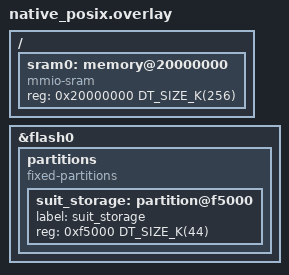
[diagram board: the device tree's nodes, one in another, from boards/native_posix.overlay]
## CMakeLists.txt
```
#
# Copyright (c) 2022 Nordic Semiconductor ASA
#
# SPDX-License-Identifier: LicenseRef-Nordic-5-Clause
#

cmake_minimum_required(VERSION 3.20.0)

find_package(Zephyr REQUIRED HINTS $ENV{ZEPHYR_BASE})

project(integration_test_suit_storage)
include(../cmake/test_template.cmake)

# Link with the CMake target, that includes SUIT platform internal APIs header
zephyr_library_link_libraries(suit_utils)
zephyr_library_link_libraries(suit_storage_interface)
zephyr_library_link_libraries(suit_update_magic_values)
```

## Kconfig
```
#
# Copyright (c) 2025 Nordic Semiconductor ASA
#
# SPDX-License-Identifier: LicenseRef-Nordic-5-Clause
#

rsource "../tests/Kconfig"

source "Kconfig.zephyr"
```

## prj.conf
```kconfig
#
# Copyright (c) 2022 Nordic Semiconductor ASA
#
# SPDX-License-Identifier: LicenseRef-Nordic-5-Clause
#

CONFIG_ZTEST=y

CONFIG_SUIT=y
CONFIG_SUIT_UTILS=y
CONFIG_SUIT_STORAGE=y
CONFIG_SUIT_STORAGE_N_UPDATE_REGIONS=3
CONFIG_SUIT_METADATA=y

CONFIG_ZCBOR=y
CONFIG_ZCBOR_CANONICAL=y

CONFIG_FLASH=y
```

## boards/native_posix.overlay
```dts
/*
 * Copyright (c) 2022 Nordic Semiconductor ASA
 *
 * SPDX-License-Identifier: LicenseRef-Nordic-5-Clause
 */

&flash0 {
	partitions {
		compatible = "fixed-partitions";
		#address-cells = <1>;
		#size-cells = <1>;

		/* Use the last 44KB of NVM as suit storage. */
		suit_storage: partition@f5000 {
			label = "suit_storage";
			reg = <0xf5000 DT_SIZE_K(44)>;
		};
	};
};

/ {
	sram0: memory@20000000 {
		compatible = "mmio-sram";
		reg = <0x20000000 DT_SIZE_K(256)>;
	};
};
```

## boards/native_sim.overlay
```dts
/*
 * Copyright (c) 2022 Nordic Semiconductor ASA
 *
 * SPDX-License-Identifier: LicenseRef-Nordic-5-Clause
 */

&flash0 {
	partitions {
		compatible = "fixed-partitions";
		#address-cells = <1>;
		#size-cells = <1>;

		/* Use the last 48KB of NVM as suit storage. */
		suit_storage: partition@f4000 {
			reg = <0xf4000 DT_SIZE_K(48)>;
		};
	};
};

/ {
	sram0: memory@20000000 {
		compatible = "mmio-sram";
		reg = <0x20000000 DT_SIZE_K(256)>;
	};
};
```

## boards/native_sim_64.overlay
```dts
/*
 * Copyright (c) 2022 Nordic Semiconductor ASA
 *
 * SPDX-License-Identifier: LicenseRef-Nordic-5-Clause
 */

&flash0 {
	partitions {
		compatible = "fixed-partitions";
		#address-cells = <1>;
		#size-cells = <1>;

		/* Use the last 44KB of NVM as suit storage. */
		suit_storage: partition@f5000 {
			reg = <0xf5000 DT_SIZE_K(44)>;
		};
	};
};

/ {
	sram0: memory@20000000 {
		compatible = "mmio-sram";
		reg = <0x20000000 DT_SIZE_K(256)>;
	};
};
```

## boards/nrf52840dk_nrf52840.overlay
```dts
/*
 * Copyright (c) 2022 Nordic Semiconductor ASA
 *
 * SPDX-License-Identifier: LicenseRef-Nordic-5-Clause
 */

&flash0 {
	partitions {
		compatible = "fixed-partitions";
		#address-cells = <1>;
		#size-cells = <1>;

		/* Use the last 48KB of NVM as suit storage. */
		suit_storage: partition@f4000 {
			reg = <0xf4000 DT_SIZE_K(48)>;
		};
	};
};
```

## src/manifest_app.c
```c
/*
 * Copyright (c) 2023 Nordic Semiconductor ASA
 *
 * SPDX-License-Identifier: LicenseRef-Nordic-5-Clause
 */

#include <stdint.h>
#include <stddef.h>

/** @brief SUIT envelope generated using the manifest/manifest_app.yaml input file.
 *
 * @details This envelope contains 256-byte random numbers attached as an integrated
 *          payload and fetched directly into the memory-mapped region during install step.
 *          The envelope has been signed using the manifest/key_private.pem key.
 *
 * @note Please use the manifest_common/regenerate.sh script for regenerating payloads.
 */
uint8_t manifest_app_buf[] = {
	0xD8, 0x6B, 0xA4, 0x02, 0x58, 0x7A, 0x82, 0x58, 0x24, 0x82, 0x2F, 0x58, 0x20, 0x4E, 0xDE,
	0x20, 0x62, 0xD7, 0x21, 0x32, 0xB2, 0xF4, 0x4C, 0x2C, 0x8B, 0x10, 0x41, 0xB1, 0x76, 0x3C,
	0x6E, 0x42, 0x2A, 0x82, 0xE9, 0x95, 0x91, 0x2B, 0x3B, 0x3A, 0x41, 0xC7, 0x96, 0xA3, 0x9B,
	0x58, 0x51, 0xD2, 0x84, 0x4A, 0xA2, 0x01, 0x26, 0x04, 0x45, 0x1A, 0x40, 0x02, 0x21, 0x00,
	0xA0, 0xF6, 0x58, 0x40, 0x39, 0x9A, 0x16, 0x37, 0xEC, 0x61, 0xA4, 0x17, 0x40, 0x22, 0xE7,
	0x0B, 0xA4, 0x9F, 0x37, 0x93, 0xC9, 0x32, 0xD9, 0x6A, 0x16, 0x42, 0x10, 0x2E, 0xB9, 0x59,
	0x62, 0x1C, 0x04, 0x30, 0x5D, 0xB8, 0x8A, 0x86, 0x95, 0xEB, 0x5C, 0xFC, 0x99, 0x9C, 0xE3,
	0x23, 0x00, 0xB3, 0xDB, 0xE7, 0xC0, 0x60, 0x56, 0x72, 0x6D, 0x7C, 0xD0, 0x94, 0x69, 0xB1,
	0x72, 0x64, 0xDD, 0x79, 0x44, 0x05, 0x18, 0xBC, 0x03, 0x58, 0xDB, 0xA8, 0x01, 0x01, 0x02,
	0x01, 0x03, 0x58, 0x70, 0xA2, 0x02, 0x81, 0x84, 0x44, 0x63, 0x4D, 0x45, 0x4D, 0x41, 0x02,
	0x45, 0x1A, 0x0E, 0x0A, 0xA0, 0x00, 0x45, 0x1A, 0x00, 0x07, 0xF8, 0x00, 0x04, 0x58, 0x56,
	0x86, 0x14, 0xA4, 0x01, 0x50, 0x76, 0x17, 0xDA, 0xA5, 0x71, 0xFD, 0x5A, 0x85, 0x8F, 0x94,
	0xE2, 0x8D, 0x73, 0x5C, 0xE9, 0xF4, 0x02, 0x50, 0x08, 0xC1, 0xB5, 0x99, 0x55, 0xE8, 0x5F,
	0xBC, 0x9E, 0x76, 0x7B, 0xC2, 0x9C, 0xE1, 0xB0, 0x4D, 0x03, 0x58, 0x24, 0x82, 0x2F, 0x58,
	0x20, 0x5F, 0xC3, 0x54, 0xBF, 0x8E, 0x8C, 0x50, 0xFB, 0x4F, 0xBC, 0x2C, 0xFA, 0xEB, 0x04,
	0x53, 0x41, 0xC9, 0x80, 0x6D, 0xEA, 0xBD, 0xCB, 0x41, 0x54, 0xFB, 0x79, 0xCC, 0xA4, 0xF0,
	0xC9, 0x8C, 0x12, 0x0E, 0x19, 0x01, 0x00, 0x01, 0x0F, 0x02, 0x0F, 0x07, 0x43, 0x82, 0x03,
	0x0F, 0x09, 0x43, 0x82, 0x17, 0x02, 0x11, 0x52, 0x86, 0x14, 0xA1, 0x15, 0x69, 0x23, 0x66,
	0x69, 0x6C, 0x65, 0x2E, 0x62, 0x69, 0x6E, 0x15, 0x02, 0x03, 0x0F, 0x17, 0x82, 0x2F, 0x58,
	0x20, 0x47, 0x37, 0x59, 0x1A, 0x1E, 0x62, 0xE1, 0x47, 0xD3, 0x22, 0x73, 0xA9, 0x14, 0x4C,
	0x55, 0xD9, 0x90, 0xA8, 0x51, 0x41, 0x8C, 0x82, 0x68, 0x30, 0x4C, 0xE1, 0x6F, 0x23, 0x6F,
	0x26, 0x5D, 0x13, 0x05, 0x82, 0x4C, 0x6B, 0x49, 0x4E, 0x53, 0x54, 0x4C, 0x44, 0x5F, 0x4D,
	0x46, 0x53, 0x54, 0x50, 0x08, 0xC1, 0xB5, 0x99, 0x55, 0xE8, 0x5F, 0xBC, 0x9E, 0x76, 0x7B,
	0xC2, 0x9C, 0xE1, 0xB0, 0x4D, 0x17, 0x58, 0x9B, 0xA1, 0x62, 0x65, 0x6E, 0xA1, 0x84, 0x44,
	0x63, 0x4D, 0x45, 0x4D, 0x41, 0x02, 0x45, 0x1A, 0x0E, 0x0A, 0xA0, 0x00, 0x45, 0x1A, 0x00,
	0x07, 0xF8, 0x00, 0xA6, 0x01, 0x78, 0x18, 0x4E, 0x6F, 0x72, 0x64, 0x69, 0x63, 0x20, 0x53,
	0x65, 0x6D, 0x69, 0x63, 0x6F, 0x6E, 0x64, 0x75, 0x63, 0x74, 0x6F, 0x72, 0x20, 0x41, 0x53,
	0x41, 0x02, 0x6F, 0x6E, 0x52, 0x46, 0x35, 0x34, 0x48, 0x32, 0x30, 0x5F, 0x63, 0x70, 0x75,
	0x61, 0x70, 0x70, 0x03, 0x6E, 0x6E, 0x6F, 0x72, 0x64, 0x69, 0x63, 0x73, 0x65, 0x6D, 0x69,
	0x2E, 0x63, 0x6F, 0x6D, 0x04, 0x78, 0x1D, 0x54, 0x68, 0x65, 0x20, 0x6E, 0x52, 0x46, 0x35,
	0x34, 0x48, 0x32, 0x30, 0x20, 0x61, 0x70, 0x70, 0x6C, 0x69, 0x63, 0x61, 0x74, 0x69, 0x6F,
	0x6E, 0x20, 0x63, 0x6F, 0x72, 0x65, 0x05, 0x78, 0x1A, 0x53, 0x61, 0x6D, 0x70, 0x6C, 0x65,
	0x20, 0x61, 0x70, 0x70, 0x6C, 0x69, 0x63, 0x61, 0x74, 0x69, 0x6F, 0x6E, 0x20, 0x63, 0x6F,
	0x72, 0x65, 0x20, 0x46, 0x57, 0x06, 0x66, 0x76, 0x31, 0x2E, 0x30, 0x2E, 0x30, 0x69, 0x23,
	0x66, 0x69, 0x6C, 0x65, 0x2E, 0x62, 0x69, 0x6E, 0x59, 0x01, 0x00, 0xC7, 0x9C, 0xAB, 0x9D,
	0xE8, 0x33, 0x7F, 0x30, 0x14, 0xEB, 0xAC, 0x02, 0xAF, 0x26, 0x01, 0x5E, 0x80, 0x6D, 0x88,
	0xA1, 0xDB, 0x11, 0xA7, 0x31, 0xDF, 0xA6, 0xEC, 0xCB, 0x9B, 0x48, 0x0D, 0xC8, 0x34, 0x40,
	0x6D, 0x30, 0x86, 0x7D, 0xE8, 0x1B, 0xEC, 0x3C, 0xF5, 0x40, 0xD0, 0x48, 0x18, 0x82, 0x11,
	0x9D, 0x7C, 0x3F, 0x6C, 0xE5, 0x8F, 0xF1, 0xD3, 0x5D, 0xE1, 0x51, 0xF7, 0x6A, 0x0F, 0xAF,
	0x0B, 0xBD, 0x4C, 0x5F, 0xA5, 0x34, 0x1A, 0x66, 0xDB, 0x22, 0xEC, 0x63, 0xED, 0x4B, 0xAB,
	0xC7, 0xC8, 0xF7, 0x59, 0xD8, 0xD6, 0x9E, 0xEC, 0x71, 0x1B, 0x24, 0x20, 0xB9, 0xAE, 0xE1,
	0x3B, 0xFC, 0xAE, 0xB8, 0x77, 0xAC, 0xA4, 0x57, 0x34, 0x97, 0x84, 0x4F, 0x58, 0xD5, 0x68,
	0x08, 0x6F, 0xE3, 0x9C, 0x7E, 0x1B, 0xD7, 0x38, 0x22, 0x98, 0x48, 0xF8, 0x7A, 0x67, 0xB2,
	0xD9, 0xAC, 0xC5, 0x34, 0xC1, 0x27, 0x82, 0x8E, 0x42, 0x79, 0x84, 0x21, 0x37, 0x4C, 0x41,
	0x4A, 0x0F, 0xE2, 0x7F, 0xA0, 0x6A, 0x19, 0x13, 0x3D, 0x52, 0x22, 0x7F, 0xD6, 0x2F, 0x71,
	0x12, 0x76, 0xAB, 0x25, 0x9C, 0xFC, 0x67, 0x08, 0x03, 0x7C, 0xDB, 0x18, 0xE6, 0x45, 0xF8,
	0x99, 0xC2, 0x9E, 0x2C, 0xE3, 0x9B, 0x25, 0xA9, 0x7B, 0x09, 0xFF, 0x00, 0x57, 0x26, 0x08,
	0x0A, 0x11, 0x42, 0xCF, 0x82, 0xA2, 0x6B, 0x2A, 0x99, 0xF9, 0x71, 0x9D, 0x14, 0x19, 0x5C,
	0x5C, 0x78, 0x31, 0x60, 0x42, 0x4A, 0x18, 0x1F, 0xEC, 0x78, 0x6A, 0x9A, 0x7C, 0x4F, 0xCF,
	0xE8, 0x5A, 0x29, 0x65, 0xCD, 0x01, 0x3B, 0x6D, 0x53, 0xBB, 0xC6, 0xDB, 0xDA, 0xD5, 0x8F,
	0xF7, 0xF4, 0xD9, 0xB9, 0x0A, 0x03, 0x4B, 0xFF, 0x33, 0xAB, 0x3B, 0xC5, 0xAF, 0xD0, 0xB8,
	0x2C, 0x0F, 0x6A, 0xA9, 0x11, 0xB0, 0xE8, 0x57, 0x8C, 0x92, 0x53, 0x81};

const size_t manifest_app_len = sizeof(manifest_app_buf);
```

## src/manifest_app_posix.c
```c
/*
 * Copyright (c) 2023 Nordic Semiconductor ASA
 *
 * SPDX-License-Identifier: LicenseRef-Nordic-5-Clause
 */

#include <stdint.h>
#include <stddef.h>

/** @brief SUIT envelope generated using the manifest/manifest_app_posix.yaml input file.
 *
 * @details This envelope contains 256-byte random numbers attached as an integrated
 *          payload and fetched directly into the memory-mapped region during install step.
 *          The envelope has been signed using the manifest/key_private.pem key.
 *
 * @note Please use the manifest_common/regenerate.sh script for regenerating payloads.
 */
uint8_t manifest_app_posix_buf[] = {
	0xD8, 0x6B, 0xA4, 0x02, 0x58, 0x7A, 0x82, 0x58, 0x24, 0x82, 0x2F, 0x58, 0x20, 0xDF, 0x79,
	0x9F, 0x6C, 0xEB, 0x40, 0x2C, 0x68, 0x1F, 0x1A, 0x36, 0x49, 0x79, 0x88, 0x83, 0xF3, 0x8A,
	0x6D, 0xA9, 0x81, 0x08, 0xA1, 0xA8, 0xE3, 0x72, 0xA0, 0xF7, 0x01, 0x27, 0x4C, 0xE9, 0x75,
	0x58, 0x51, 0xD2, 0x84, 0x4A, 0xA2, 0x01, 0x26, 0x04, 0x45, 0x1A, 0x40, 0x00, 0x00, 0x00,
	0xA0, 0xF6, 0x58, 0x40, 0xB6, 0xA9, 0xAB, 0x2B, 0xCA, 0x46, 0xB7, 0xCE, 0x18, 0x3D, 0xF1,
	0x42, 0xA1, 0xFE, 0xFE, 0x8F, 0x92, 0x4E, 0xC4, 0x3F, 0x96, 0xA9, 0x63, 0xFC, 0xD2, 0x1C,
	0xDC, 0x05, 0x07, 0x09, 0x38, 0x3C, 0x8B, 0x4D, 0x73, 0xEC, 0xF8, 0x90, 0x59, 0xCB, 0x4A,
	0x58, 0x61, 0xA6, 0x31, 0x55, 0xE4, 0xD3, 0xCF, 0xF2, 0xAA, 0x20, 0xDD, 0x4D, 0x51, 0x1B,
	0xC6, 0xF4, 0x16, 0x22, 0x65, 0x0E, 0x16, 0x48, 0x03, 0x58, 0xD9, 0xA8, 0x01, 0x01, 0x02,
	0x01, 0x03, 0x58, 0x6E, 0xA2, 0x02, 0x81, 0x84, 0x44, 0x63, 0x4D, 0x45, 0x4D, 0x41, 0x00,
	0x45, 0x1A, 0x00, 0x08, 0x00, 0x00, 0x43, 0x19, 0x10, 0x00, 0x04, 0x58, 0x56, 0x86, 0x14,
	0xA4, 0x01, 0x50, 0x76, 0x17, 0xDA, 0xA5, 0x71, 0xFD, 0x5A, 0x85, 0x8F, 0x94, 0xE2, 0x8D,
	0x73, 0x5C, 0xE9, 0xF4, 0x02, 0x50, 0x5B, 0x46, 0x9F, 0xD1, 0x90, 0xEE, 0x53, 0x9C, 0xA3,
	0x18, 0x68, 0x1B, 0x03, 0x69, 0x5E, 0x36, 0x03, 0x58, 0x24, 0x82, 0x2F, 0x58, 0x20, 0x5F,
	0xC3, 0x54, 0xBF, 0x8E, 0x8C, 0x50, 0xFB, 0x4F, 0xBC, 0x2C, 0xFA, 0xEB, 0x04, 0x53, 0x41,
	0xC9, 0x80, 0x6D, 0xEA, 0xBD, 0xCB, 0x41, 0x54, 0xFB, 0x79, 0xCC, 0xA4, 0xF0, 0xC9, 0x8C,
	0x12, 0x0E, 0x19, 0x01, 0x00, 0x01, 0x0F, 0x02, 0x0F, 0x07, 0x43, 0x82, 0x03, 0x0F, 0x09,
	0x43, 0x82, 0x17, 0x02, 0x11, 0x52, 0x86, 0x14, 0xA1, 0x15, 0x69, 0x23, 0x66, 0x69, 0x6C,
	0x65, 0x2E, 0x62, 0x69, 0x6E, 0x15, 0x02, 0x03, 0x0F, 0x17, 0x82, 0x2F, 0x58, 0x20, 0x62,
	0x2B, 0x04, 0x96, 0xCA, 0x8F, 0x04, 0xCF, 0x83, 0x2F, 0x65, 0x90, 0xD2, 0x2A, 0x16, 0x52,
	0x51, 0xB5, 0xA9, 0xFB, 0x08, 0xF6, 0xE4, 0x35, 0x3D, 0x01, 0xE3, 0x3E, 0xA7, 0xCA, 0xC5,
	0x86, 0x05, 0x82, 0x4C, 0x6B, 0x49, 0x4E, 0x53, 0x54, 0x4C, 0x44, 0x5F, 0x4D, 0x46, 0x53,
	0x54, 0x50, 0x5B, 0x46, 0x9F, 0xD1, 0x90, 0xEE, 0x53, 0x9C, 0xA3, 0x18, 0x68, 0x1B, 0x03,
	0x69, 0x5E, 0x36, 0x17, 0x58, 0x88, 0xA1, 0x62, 0x65, 0x6E, 0xA1, 0x84, 0x44, 0x63, 0x4D,
	0x45, 0x4D, 0x41, 0x00, 0x45, 0x1A, 0x00, 0x08, 0x00, 0x00, 0x43, 0x19, 0x10, 0x00, 0xA6,
	0x01, 0x78, 0x18, 0x4E, 0x6F, 0x72, 0x64, 0x69, 0x63, 0x20, 0x53, 0x65, 0x6D, 0x69, 0x63,
	0x6F, 0x6E, 0x64, 0x75, 0x63, 0x74, 0x6F, 0x72, 0x20, 0x41, 0x53, 0x41, 0x02, 0x65, 0x70,
	0x6F, 0x73, 0x69, 0x78, 0x03, 0x6E, 0x6E, 0x6F, 0x72, 0x64, 0x69, 0x63, 0x73, 0x65, 0x6D,
	0x69, 0x2E, 0x63, 0x6F, 0x6D, 0x04, 0x75, 0x54, 0x68, 0x65, 0x20, 0x50, 0x4F, 0x53, 0x49,
	0x58, 0x20, 0x61, 0x70, 0x70, 0x6C, 0x69, 0x63, 0x61, 0x74, 0x69, 0x6F, 0x6E, 0x05, 0x78,
	0x1C, 0x53, 0x61, 0x6D, 0x70, 0x6C, 0x65, 0x20, 0x61, 0x70, 0x70, 0x6C, 0x69, 0x63, 0x61,
	0x74, 0x69, 0x6F, 0x6E, 0x20, 0x66, 0x6F, 0x72, 0x20, 0x50, 0x4F, 0x53, 0x49, 0x58, 0x06,
	0x66, 0x76, 0x31, 0x2E, 0x30, 0x2E, 0x30, 0x69, 0x23, 0x66, 0x69, 0x6C, 0x65, 0x2E, 0x62,
	0x69, 0x6E, 0x59, 0x01, 0x00, 0xC7, 0x9C, 0xAB, 0x9D, 0xE8, 0x33, 0x7F, 0x30, 0x14, 0xEB,
	0xAC, 0x02, 0xAF, 0x26, 0x01, 0x5E, 0x80, 0x6D, 0x88, 0xA1, 0xDB, 0x11, 0xA7, 0x31, 0xDF,
	0xA6, 0xEC, 0xCB, 0x9B, 0x48, 0x0D, 0xC8, 0x34, 0x40, 0x6D, 0x30, 0x86, 0x7D, 0xE8, 0x1B,
	0xEC, 0x3C, 0xF5, 0x40, 0xD0, 0x48, 0x18, 0x82, 0x11, 0x9D, 0x7C, 0x3F, 0x6C, 0xE5, 0x8F,
	0xF1, 0xD3, 0x5D, 0xE1, 0x51, 0xF7, 0x6A, 0x0F, 0xAF, 0x0B, 0xBD, 0x4C, 0x5F, 0xA5, 0x34,
	0x1A, 0x66, 0xDB, 0x22, 0xEC, 0x63, 0xED, 0x4B, 0xAB, 0xC7, 0xC8, 0xF7, 0x59, 0xD8, 0xD6,
	0x9E, 0xEC, 0x71, 0x1B, 0x24, 0x20, 0xB9, 0xAE, 0xE1, 0x3B, 0xFC, 0xAE, 0xB8, 0x77, 0xAC,
	0xA4, 0x57, 0x34, 0x97, 0x84, 0x4F, 0x58, 0xD5, 0x68, 0x08, 0x6F, 0xE3, 0x9C, 0x7E, 0x1B,
	0xD7, 0x38, 0x22, 0x98, 0x48, 0xF8, 0x7A, 0x67, 0xB2, 0xD9, 0xAC, 0xC5, 0x34, 0xC1, 0x27,
	0x82, 0x8E, 0x42, 0x79, 0x84, 0x21, 0x37, 0x4C, 0x41, 0x4A, 0x0F, 0xE2, 0x7F, 0xA0, 0x6A,
	0x19, 0x13, 0x3D, 0x52, 0x22, 0x7F, 0xD6, 0x2F, 0x71, 0x12, 0x76, 0xAB, 0x25, 0x9C, 0xFC,
	0x67, 0x08, 0x03, 0x7C, 0xDB, 0x18, 0xE6, 0x45, 0xF8, 0x99, 0xC2, 0x9E, 0x2C, 0xE3, 0x9B,
	0x25, 0xA9, 0x7B, 0x09, 0xFF, 0x00, 0x57, 0x26, 0x08, 0x0A, 0x11, 0x42, 0xCF, 0x82, 0xA2,
	0x6B, 0x2A, 0x99, 0xF9, 0x71, 0x9D, 0x14, 0x19, 0x5C, 0x5C, 0x78, 0x31, 0x60, 0x42, 0x4A,
	0x18, 0x1F, 0xEC, 0x78, 0x6A, 0x9A, 0x7C, 0x4F, 0xCF, 0xE8, 0x5A, 0x29, 0x65, 0xCD, 0x01,
	0x3B, 0x6D, 0x53, 0xBB, 0xC6, 0xDB, 0xDA, 0xD5, 0x8F, 0xF7, 0xF4, 0xD9, 0xB9, 0x0A, 0x03,
	0x4B, 0xFF, 0x33, 0xAB, 0x3B, 0xC5, 0xAF, 0xD0, 0xB8, 0x2C, 0x0F, 0x6A, 0xA9, 0x11, 0xB0,
	0xE8, 0x57, 0x8C, 0x92, 0x53, 0x81};

const size_t manifest_app_posix_len = sizeof(manifest_app_posix_buf);
```

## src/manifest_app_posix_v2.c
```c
/*
 * Copyright (c) 2024 Nordic Semiconductor ASA
 *
 * SPDX-License-Identifier: LicenseRef-Nordic-5-Clause
 */

#include <stdint.h>
#include <stddef.h>

/** @brief SUIT envelope generated using the manifest/manifest_app_posix_v2.yaml input file.
 *
 * @details This envelope contains 256-byte random numbers attached as an integrated
 *          payload and fetched directly into the memory-mapped region during install step.
 *          The envelope has been signed using the manifest/key_private.pem key.
 *
 * @note Please use the manifest_common/regenerate.sh script for regenerating payloads.
 */
uint8_t manifest_app_posix_v2_buf[] = {
	0xD8, 0x6B, 0xA4, 0x02, 0x58, 0x7A, 0x82, 0x58, 0x24, 0x82, 0x2F, 0x58, 0x20, 0xF7, 0x1F,
	0x7D, 0xC3, 0x77, 0x29, 0xF6, 0x7E, 0x16, 0xF1, 0x1A, 0x6C, 0xA8, 0x3F, 0xC7, 0x20, 0xC7,
	0xFC, 0x04, 0xD3, 0xC2, 0x2E, 0x4B, 0xA2, 0xCC, 0x00, 0xA9, 0x02, 0x11, 0x79, 0x8C, 0x96,
	0x58, 0x51, 0xD2, 0x84, 0x4A, 0xA2, 0x01, 0x26, 0x04, 0x45, 0x1A, 0x40, 0x00, 0x00, 0x00,
	0xA0, 0xF6, 0x58, 0x40, 0xD8, 0xCE, 0x24, 0x64, 0x7B, 0x2E, 0x7B, 0x1D, 0x6C, 0x40, 0x25,
	0x79, 0xEE, 0xB0, 0xFB, 0xFB, 0xD2, 0x1E, 0xED, 0x35, 0x70, 0x8F, 0x20, 0x95, 0x81, 0x09,
	0x21, 0x04, 0xC7, 0xD7, 0xD3, 0x7F, 0xCD, 0xBE, 0x69, 0x31, 0xB9, 0x7D, 0x71, 0xAA, 0x3A,
	0x50, 0x2D, 0xEB, 0x67, 0x78, 0x63, 0x27, 0x36, 0xBF, 0x72, 0xF5, 0x0A, 0x65, 0x11, 0x3C,
	0x70, 0xC0, 0x99, 0xA0, 0xFA, 0x9F, 0x72, 0xA1, 0x03, 0x58, 0xD9, 0xA8, 0x01, 0x01, 0x02,
	0x02, 0x03, 0x58, 0x6E, 0xA2, 0x02, 0x81, 0x84, 0x44, 0x63, 0x4D, 0x45, 0x4D, 0x41, 0x00,
	0x45, 0x1A, 0x00, 0x08, 0x00, 0x00, 0x43, 0x19, 0x10, 0x00, 0x04, 0x58, 0x56, 0x86, 0x14,
	0xA4, 0x01, 0x50, 0x76, 0x17, 0xDA, 0xA5, 0x71, 0xFD, 0x5A, 0x85, 0x8F, 0x94, 0xE2, 0x8D,
	0x73, 0x5C, 0xE9, 0xF4, 0x02, 0x50, 0x5B, 0x46, 0x9F, 0xD1, 0x90, 0xEE, 0x53, 0x9C, 0xA3,
	0x18, 0x68, 0x1B, 0x03, 0x69, 0x5E, 0x36, 0x03, 0x58, 0x24, 0x82, 0x2F, 0x58, 0x20, 0x5F,
	0xC3, 0x54, 0xBF, 0x8E, 0x8C, 0x50, 0xFB, 0x4F, 0xBC, 0x2C, 0xFA, 0xEB, 0x04, 0x53, 0x41,
	0xC9, 0x80, 0x6D, 0xEA, 0xBD, 0xCB, 0x41, 0x54, 0xFB, 0x79, 0xCC, 0xA4, 0xF0, 0xC9, 0x8C,
	0x12, 0x0E, 0x19, 0x01, 0x00, 0x01, 0x0F, 0x02, 0x0F, 0x07, 0x43, 0x82, 0x03, 0x0F, 0x09,
	0x43, 0x82, 0x17, 0x02, 0x11, 0x52, 0x86, 0x14, 0xA1, 0x15, 0x69, 0x23, 0x66, 0x69, 0x6C,
	0x65, 0x2E, 0x62, 0x69, 0x6E, 0x15, 0x02, 0x03, 0x0F, 0x17, 0x82, 0x2F, 0x58, 0x20, 0x62,
	0x2B, 0x04, 0x96, 0xCA, 0x8F, 0x04, 0xCF, 0x83, 0x2F, 0x65, 0x90, 0xD2, 0x2A, 0x16, 0x52,
	0x51, 0xB5, 0xA9, 0xFB, 0x08, 0xF6, 0xE4, 0x35, 0x3D, 0x01, 0xE3, 0x3E, 0xA7, 0xCA, 0xC5,
	0x86, 0x05, 0x82, 0x4C, 0x6B, 0x49, 0x4E, 0x53, 0x54, 0x4C, 0x44, 0x5F, 0x4D, 0x46, 0x53,
	0x54, 0x50, 0x5B, 0x46, 0x9F, 0xD1, 0x90, 0xEE, 0x53, 0x9C, 0xA3, 0x18, 0x68, 0x1B, 0x03,
	0x69, 0x5E, 0x36, 0x17, 0x58, 0x88, 0xA1, 0x62, 0x65, 0x6E, 0xA1, 0x84, 0x44, 0x63, 0x4D,
	0x45, 0x4D, 0x41, 0x00, 0x45, 0x1A, 0x00, 0x08, 0x00, 0x00, 0x43, 0x19, 0x10, 0x00, 0xA6,
	0x01, 0x78, 0x18, 0x4E, 0x6F, 0x72, 0x64, 0x69, 0x63, 0x20, 0x53, 0x65, 0x6D, 0x69, 0x63,
	0x6F, 0x6E, 0x64, 0x75, 0x63, 0x74, 0x6F, 0x72, 0x20, 0x41, 0x53, 0x41, 0x02, 0x65, 0x70,
	0x6F, 0x73, 0x69, 0x78, 0x03, 0x6E, 0x6E, 0x6F, 0x72, 0x64, 0x69, 0x63, 0x73, 0x65, 0x6D,
	0x69, 0x2E, 0x63, 0x6F, 0x6D, 0x04, 0x75, 0x54, 0x68, 0x65, 0x20, 0x50, 0x4F, 0x53, 0x49,
	0x58, 0x20, 0x61, 0x70, 0x70, 0x6C, 0x69, 0x63, 0x61, 0x74, 0x69, 0x6F, 0x6E, 0x05, 0x78,
	0x1C, 0x53, 0x61, 0x6D, 0x70, 0x6C, 0x65, 0x20, 0x61, 0x70, 0x70, 0x6C, 0x69, 0x63, 0x61,
	0x74, 0x69, 0x6F, 0x6E, 0x20, 0x66, 0x6F, 0x72, 0x20, 0x50, 0x4F, 0x53, 0x49, 0x58, 0x06,
	0x66, 0x76, 0x31, 0x2E, 0x30, 0x2E, 0x30, 0x69, 0x23, 0x66, 0x69, 0x6C, 0x65, 0x2E, 0x62,
	0x69, 0x6E, 0x59, 0x01, 0x00, 0xC7, 0x9C, 0xAB, 0x9D, 0xE8, 0x33, 0x7F, 0x30, 0x14, 0xEB,
	0xAC, 0x02, 0xAF, 0x26, 0x01, 0x5E, 0x80, 0x6D, 0x88, 0xA1, 0xDB, 0x11, 0xA7, 0x31, 0xDF,
	0xA6, 0xEC, 0xCB, 0x9B, 0x48, 0x0D, 0xC8, 0x34, 0x40, 0x6D, 0x30, 0x86, 0x7D, 0xE8, 0x1B,
	0xEC, 0x3C, 0xF5, 0x40, 0xD0, 0x48, 0x18, 0x82, 0x11, 0x9D, 0x7C, 0x3F, 0x6C, 0xE5, 0x8F,
	0xF1, 0xD3, 0x5D, 0xE1, 0x51, 0xF7, 0x6A, 0x0F, 0xAF, 0x0B, 0xBD, 0x4C, 0x5F, 0xA5, 0x34,
	0x1A, 0x66, 0xDB, 0x22, 0xEC, 0x63, 0xED, 0x4B, 0xAB, 0xC7, 0xC8, 0xF7, 0x59, 0xD8, 0xD6,
	0x9E, 0xEC, 0x71, 0x1B, 0x24, 0x20, 0xB9, 0xAE, 0xE1, 0x3B, 0xFC, 0xAE, 0xB8, 0x77, 0xAC,
	0xA4, 0x57, 0x34, 0x97, 0x84, 0x4F, 0x58, 0xD5, 0x68, 0x08, 0x6F, 0xE3, 0x9C, 0x7E, 0x1B,
	0xD7, 0x38, 0x22, 0x98, 0x48, 0xF8, 0x7A, 0x67, 0xB2, 0xD9, 0xAC, 0xC5, 0x34, 0xC1, 0x27,
	0x82, 0x8E, 0x42, 0x79, 0x84, 0x21, 0x37, 0x4C, 0x41, 0x4A, 0x0F, 0xE2, 0x7F, 0xA0, 0x6A,
	0x19, 0x13, 0x3D, 0x52, 0x22, 0x7F, 0xD6, 0x2F, 0x71, 0x12, 0x76, 0xAB, 0x25, 0x9C, 0xFC,
	0x67, 0x08, 0x03, 0x7C, 0xDB, 0x18, 0xE6, 0x45, 0xF8, 0x99, 0xC2, 0x9E, 0x2C, 0xE3, 0x9B,
	0x25, 0xA9, 0x7B, 0x09, 0xFF, 0x00, 0x57, 0x26, 0x08, 0x0A, 0x11, 0x42, 0xCF, 0x82, 0xA2,
	0x6B, 0x2A, 0x99, 0xF9, 0x71, 0x9D, 0x14, 0x19, 0x5C, 0x5C, 0x78, 0x31, 0x60, 0x42, 0x4A,
	0x18, 0x1F, 0xEC, 0x78, 0x6A, 0x9A, 0x7C, 0x4F, 0xCF, 0xE8, 0x5A, 0x29, 0x65, 0xCD, 0x01,
	0x3B, 0x6D, 0x53, 0xBB, 0xC6, 0xDB, 0xDA, 0xD5, 0x8F, 0xF7, 0xF4, 0xD9, 0xB9, 0x0A, 0x03,
	0x4B, 0xFF, 0x33, 0xAB, 0x3B, 0xC5, 0xAF, 0xD0, 0xB8, 0x2C, 0x0F, 0x6A, 0xA9, 0x11, 0xB0,
	0xE8, 0x57, 0x8C, 0x92, 0x53, 0x81};

const size_t manifest_app_posix_v2_len = sizeof(manifest_app_posix_v2_buf);
```

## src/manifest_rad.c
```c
/*
 * Copyright (c) 2023 Nordic Semiconductor ASA
 *
 * SPDX-License-Identifier: LicenseRef-Nordic-5-Clause
 */

#include <stdint.h>
#include <stddef.h>

/** @brief SUIT envelope generated using the manifest/manifest_rad.yaml input file.
 *
 * @details This envelope contains 256-byte random numbers attached as an integrated
 *          payload and fetched directly into the memory-mapped region during install step.
 *          The envelope has been signed using the manifest/key_private.pem key.
 *
 * @note Please use the manifest_common/regenerate.sh script for regenerating payloads.
 */
uint8_t manifest_rad_buf[] = {
	0xD8, 0x6B, 0xA4, 0x02, 0x58, 0x7A, 0x82, 0x58, 0x24, 0x82, 0x2F, 0x58, 0x20, 0x8A, 0x63,
	0x1C, 0x5B, 0x6D, 0xE8, 0x37, 0x82, 0xB0, 0x4A, 0xDC, 0x63, 0x26, 0xC0, 0x3D, 0xA9, 0x28,
	0x16, 0xE1, 0xA5, 0xB4, 0x2D, 0xB5, 0x7D, 0xA8, 0xA0, 0x3C, 0x19, 0x81, 0x5F, 0x8E, 0xF5,
	0x58, 0x51, 0xD2, 0x84, 0x4A, 0xA2, 0x01, 0x26, 0x04, 0x45, 0x1A, 0x40, 0x03, 0x21, 0x00,
	0xA0, 0xF6, 0x58, 0x40, 0x11, 0x6B, 0x0F, 0x84, 0x71, 0x3E, 0xA6, 0xD0, 0xA5, 0x07, 0x12,
	0x81, 0x9A, 0x0C, 0xC6, 0x0B, 0x96, 0x9D, 0x4A, 0x57, 0x5B, 0x23, 0x61, 0xC2, 0x68, 0x8C,
	0x23, 0x2A, 0xB9, 0x95, 0x2D, 0x38, 0x2B, 0x24, 0x56, 0xC6, 0xF4, 0x58, 0xAC, 0xFD, 0x22,
	0xF2, 0x7E, 0x8C, 0x76, 0x16, 0xF7, 0xF8, 0xFB, 0x66, 0xB3, 0xC9, 0x28, 0xB2, 0x17, 0x3C,
	0xA9, 0x25, 0x34, 0x6C, 0xC8, 0xDD, 0xD2, 0xF1, 0x03, 0x58, 0xDB, 0xA8, 0x01, 0x01, 0x02,
	0x01, 0x03, 0x58, 0x70, 0xA2, 0x02, 0x81, 0x84, 0x44, 0x63, 0x4D, 0x45, 0x4D, 0x41, 0x03,
	0x45, 0x1A, 0x0E, 0x05, 0x40, 0x00, 0x45, 0x1A, 0x00, 0x05, 0x58, 0x00, 0x04, 0x58, 0x56,
	0x86, 0x14, 0xA4, 0x01, 0x50, 0x76, 0x17, 0xDA, 0xA5, 0x71, 0xFD, 0x5A, 0x85, 0x8F, 0x94,
	0xE2, 0x8D, 0x73, 0x5C, 0xE9, 0xF4, 0x02, 0x50, 0x81, 0x6A, 0xA0, 0xA0, 0xAF, 0x11, 0x5E,
	0xF2, 0x85, 0x8A, 0xFE, 0xB6, 0x68, 0xB2, 0xE9, 0xC9, 0x03, 0x58, 0x24, 0x82, 0x2F, 0x58,
	0x20, 0x5F, 0xC3, 0x54, 0xBF, 0x8E, 0x8C, 0x50, 0xFB, 0x4F, 0xBC, 0x2C, 0xFA, 0xEB, 0x04,
	0x53, 0x41, 0xC9, 0x80, 0x6D, 0xEA, 0xBD, 0xCB, 0x41, 0x54, 0xFB, 0x79, 0xCC, 0xA4, 0xF0,
	0xC9, 0x8C, 0x12, 0x0E, 0x19, 0x01, 0x00, 0x01, 0x0F, 0x02, 0x0F, 0x07, 0x43, 0x82, 0x03,
	0x0F, 0x09, 0x43, 0x82, 0x17, 0x02, 0x11, 0x52, 0x86, 0x14, 0xA1, 0x15, 0x69, 0x23, 0x66,
	0x69, 0x6C, 0x65, 0x2E, 0x62, 0x69, 0x6E, 0x15, 0x02, 0x03, 0x0F, 0x17, 0x82, 0x2F, 0x58,
	0x20, 0xCB, 0xAC, 0xBD, 0x31, 0x77, 0xE4, 0x07, 0x2A, 0xAB, 0x23, 0xE7, 0xED, 0x4B, 0x4B,
	0x25, 0x76, 0x85, 0x87, 0xCE, 0xBB, 0xD7, 0x53, 0xCD, 0x25, 0x68, 0x36, 0x51, 0xD0, 0x7B,
	0x40, 0x3D, 0x98, 0x05, 0x82, 0x4C, 0x6B, 0x49, 0x4E, 0x53, 0x54, 0x4C, 0x44, 0x5F, 0x4D,
	0x46, 0x53, 0x54, 0x50, 0x81, 0x6A, 0xA0, 0xA0, 0xAF, 0x11, 0x5E, 0xF2, 0x85, 0x8A, 0xFE,
	0xB6, 0x68, 0xB2, 0xE9, 0xC9, 0x17, 0x58, 0x8D, 0xA1, 0x62, 0x65, 0x6E, 0xA1, 0x84, 0x44,
	0x63, 0x4D, 0x45, 0x4D, 0x41, 0x03, 0x45, 0x1A, 0x0E, 0x05, 0x40, 0x00, 0x45, 0x1A, 0x00,
	0x05, 0x58, 0x00, 0xA6, 0x01, 0x78, 0x18, 0x4E, 0x6F, 0x72, 0x64, 0x69, 0x63, 0x20, 0x53,
	0x65, 0x6D, 0x69, 0x63, 0x6F, 0x6E, 0x64, 0x75, 0x63, 0x74, 0x6F, 0x72, 0x20, 0x41, 0x53,
	0x41, 0x02, 0x6F, 0x6E, 0x52, 0x46, 0x35, 0x34, 0x48, 0x32, 0x30, 0x5F, 0x63, 0x70, 0x75,
	0x72, 0x61, 0x64, 0x03, 0x6E, 0x6E, 0x6F, 0x72, 0x64, 0x69, 0x63, 0x73, 0x65, 0x6D, 0x69,
	0x2E, 0x63, 0x6F, 0x6D, 0x04, 0x77, 0x54, 0x68, 0x65, 0x20, 0x6E, 0x52, 0x46, 0x35, 0x34,
	0x48, 0x32, 0x30, 0x20, 0x72, 0x61, 0x64, 0x69, 0x6F, 0x20, 0x63, 0x6F, 0x72, 0x65, 0x05,
	0x74, 0x53, 0x61, 0x6D, 0x70, 0x6C, 0x65, 0x20, 0x72, 0x61, 0x64, 0x69, 0x6F, 0x20, 0x63,
	0x6F, 0x72, 0x65, 0x20, 0x46, 0x57, 0x06, 0x66, 0x76, 0x31, 0x2E, 0x30, 0x2E, 0x30, 0x69,
	0x23, 0x66, 0x69, 0x6C, 0x65, 0x2E, 0x62, 0x69, 0x6E, 0x59, 0x01, 0x00, 0xC7, 0x9C, 0xAB,
	0x9D, 0xE8, 0x33, 0x7F, 0x30, 0x14, 0xEB, 0xAC, 0x02, 0xAF, 0x26, 0x01, 0x5E, 0x80, 0x6D,
	0x88, 0xA1, 0xDB, 0x11, 0xA7, 0x31, 0xDF, 0xA6, 0xEC, 0xCB, 0x9B, 0x48, 0x0D, 0xC8, 0x34,
	0x40, 0x6D, 0x30, 0x86, 0x7D, 0xE8, 0x1B, 0xEC, 0x3C, 0xF5, 0x40, 0xD0, 0x48, 0x18, 0x82,
	0x11, 0x9D, 0x7C, 0x3F, 0x6C, 0xE5, 0x8F, 0xF1, 0xD3, 0x5D, 0xE1, 0x51, 0xF7, 0x6A, 0x0F,
	0xAF, 0x0B, 0xBD, 0x4C, 0x5F, 0xA5, 0x34, 0x1A, 0x66, 0xDB, 0x22, 0xEC, 0x63, 0xED, 0x4B,
	0xAB, 0xC7, 0xC8, 0xF7, 0x59, 0xD8, 0xD6, 0x9E, 0xEC, 0x71, 0x1B, 0x24, 0x20, 0xB9, 0xAE,
	0xE1, 0x3B, 0xFC, 0xAE, 0xB8, 0x77, 0xAC, 0xA4, 0x57, 0x34, 0x97, 0x84, 0x4F, 0x58, 0xD5,
	0x68, 0x08, 0x6F, 0xE3, 0x9C, 0x7E, 0x1B, 0xD7, 0x38, 0x22, 0x98, 0x48, 0xF8, 0x7A, 0x67,
	0xB2, 0xD9, 0xAC, 0xC5, 0x34, 0xC1, 0x27, 0x82, 0x8E, 0x42, 0x79, 0x84, 0x21, 0x37, 0x4C,
	0x41, 0x4A, 0x0F, 0xE2, 0x7F, 0xA0, 0x6A, 0x19, 0x13, 0x3D, 0x52, 0x22, 0x7F, 0xD6, 0x2F,
	0x71, 0x12, 0x76, 0xAB, 0x25, 0x9C, 0xFC, 0x67, 0x08, 0x03, 0x7C, 0xDB, 0x18, 0xE6, 0x45,
	0xF8, 0x99, 0xC2, 0x9E, 0x2C, 0xE3, 0x9B, 0x25, 0xA9, 0x7B, 0x09, 0xFF, 0x00, 0x57, 0x26,
	0x08, 0x0A, 0x11, 0x42, 0xCF, 0x82, 0xA2, 0x6B, 0x2A, 0x99, 0xF9, 0x71, 0x9D, 0x14, 0x19,
	0x5C, 0x5C, 0x78, 0x31, 0x60, 0x42, 0x4A, 0x18, 0x1F, 0xEC, 0x78, 0x6A, 0x9A, 0x7C, 0x4F,
	0xCF, 0xE8, 0x5A, 0x29, 0x65, 0xCD, 0x01, 0x3B, 0x6D, 0x53, 0xBB, 0xC6, 0xDB, 0xDA, 0xD5,
	0x8F, 0xF7, 0xF4, 0xD9, 0xB9, 0x0A, 0x03, 0x4B, 0xFF, 0x33, 0xAB, 0x3B, 0xC5, 0xAF, 0xD0,
	0xB8, 0x2C, 0x0F, 0x6A, 0xA9, 0x11, 0xB0, 0xE8, 0x57, 0x8C, 0x92, 0x53, 0x81};

const size_t manifest_rad_len = sizeof(manifest_rad_buf);
```

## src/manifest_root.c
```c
/*
 * Copyright (c) 2023 Nordic Semiconductor ASA
 *
 * SPDX-License-Identifier: LicenseRef-Nordic-5-Clause
 */

#include <stdint.h>
#include <stddef.h>

/** @brief SUIT envelope generated using the manifest/manifest_root.yaml input file.
 *
 * @details This envelope contains 256-byte random numbers attached as an integrated
 *          payload and fetched directly into the memory-mapped region during install step.
 *          The envelope has been signed using the manifest/key_private.pem key.
 *
 * @note Please use the manifest_common/regenerate.sh script for regenerating payloads.
 */
uint8_t manifest_root_buf[] = {
	0xD8, 0x6B, 0xA5, 0x02, 0x58, 0x7A, 0x82, 0x58, 0x24, 0x82, 0x2F, 0x58, 0x20, 0x0E, 0x18,
	0xC8, 0xF1, 0xC8, 0x26, 0x7D, 0xFC, 0x8F, 0xF8, 0xE6, 0xCE, 0xBF, 0xBF, 0xC1, 0xF9, 0x34,
	0xEB, 0x49, 0x24, 0x78, 0x12, 0x56, 0xE7, 0xE4, 0x3F, 0x52, 0x0E, 0x86, 0xAE, 0xFF, 0x5D,
	0x58, 0x51, 0xD2, 0x84, 0x4A, 0xA2, 0x01, 0x26, 0x04, 0x45, 0x1A, 0x40, 0x00, 0xAA, 0x00,
	0xA0, 0xF6, 0x58, 0x40, 0x6B, 0x85, 0xAD, 0x50, 0x0E, 0x2B, 0x93, 0xB3, 0x91, 0x0A, 0x46,
	0x7C, 0x3B, 0x11, 0x9A, 0xD4, 0x0E, 0xC6, 0x8A, 0x66, 0x5D, 0x97, 0x2D, 0xE7, 0x77, 0xE2,
	0xAB, 0x3F, 0xFA, 0x3A, 0xC1, 0x74, 0x9E, 0x16, 0x57, 0xE8, 0x56, 0x90, 0x7A, 0x71, 0x4A,
	0x74, 0x65, 0x23, 0xCA, 0xB6, 0x2E, 0x7C, 0x46, 0x7A, 0x54, 0x48, 0xC2, 0x63, 0xEE, 0x3B,
	0xE5, 0x82, 0x2F, 0x20, 0xFB, 0x8D, 0x42, 0x3C, 0x03, 0x59, 0x01, 0x94, 0xA8, 0x01, 0x01,
	0x02, 0x01, 0x03, 0x58, 0xB3, 0xA3, 0x02, 0x83, 0x82, 0x4A, 0x69, 0x43, 0x41, 0x4E, 0x44,
	0x5F, 0x4D, 0x46, 0x53, 0x54, 0x41, 0x00, 0x82, 0x4C, 0x6B, 0x49, 0x4E, 0x53, 0x54, 0x4C,
	0x44, 0x5F, 0x4D, 0x46, 0x53, 0x54, 0x50, 0x81, 0x6A, 0xA0, 0xA0, 0xAF, 0x11, 0x5E, 0xF2,
	0x85, 0x8A, 0xFE, 0xB6, 0x68, 0xB2, 0xE9, 0xC9, 0x82, 0x4C, 0x6B, 0x49, 0x4E, 0x53, 0x54,
	0x4C, 0x44, 0x5F, 0x4D, 0x46, 0x53, 0x54, 0x50, 0x08, 0xC1, 0xB5, 0x99, 0x55, 0xE8, 0x5F,
	0xBC, 0x9E, 0x76, 0x7B, 0xC2, 0x9C, 0xE1, 0xB0, 0x4D, 0x04, 0x58, 0x59, 0x8E, 0x0C, 0x01,
	0x14, 0xA2, 0x01, 0x50, 0x76, 0x17, 0xDA, 0xA5, 0x71, 0xFD, 0x5A, 0x85, 0x8F, 0x94, 0xE2,
	0x8D, 0x73, 0x5C, 0xE9, 0xF4, 0x02, 0x50, 0x81, 0x6A, 0xA0, 0xA0, 0xAF, 0x11, 0x5E, 0xF2,
	0x85, 0x8A, 0xFE, 0xB6, 0x68, 0xB2, 0xE9, 0xC9, 0x0C, 0x02, 0x14, 0xA2, 0x01, 0x50, 0x76,
	0x17, 0xDA, 0xA5, 0x71, 0xFD, 0x5A, 0x85, 0x8F, 0x94, 0xE2, 0x8D, 0x73, 0x5C, 0xE9, 0xF4,
	0x02, 0x50, 0x08, 0xC1, 0xB5, 0x99, 0x55, 0xE8, 0x5F, 0xBC, 0x9E, 0x76, 0x7B, 0xC2, 0x9C,
	0xE1, 0xB0, 0x4D, 0x0C, 0x82, 0x01, 0x02, 0x01, 0x0F, 0x02, 0x0F, 0x01, 0xA3, 0x00, 0xA0,
	0x01, 0xA0, 0x02, 0xA0, 0x07, 0x49, 0x86, 0x0C, 0x82, 0x01, 0x02, 0x07, 0x0F, 0x0B, 0x0F,
	0x09, 0x49, 0x86, 0x0C, 0x82, 0x01, 0x02, 0x07, 0x0F, 0x0B, 0x0F, 0x11, 0x58, 0x7B, 0x96,
	0x0C, 0x00, 0x14, 0xA2, 0x15, 0x69, 0x23, 0x72, 0x61, 0x64, 0x2E, 0x73, 0x75, 0x69, 0x74,
	0x03, 0x58, 0x24, 0x82, 0x2F, 0x58, 0x20, 0x64, 0x06, 0x96, 0x7A, 0x2D, 0xBD, 0xB4, 0x50,
	0xCA, 0xE3, 0xCA, 0x10, 0x4C, 0x64, 0x5F, 0xA0, 0x84, 0x69, 0x90, 0x65, 0x69, 0x7B, 0xDD,
	0x31, 0xA9, 0xE8, 0xAC, 0x7A, 0x6F, 0x4C, 0x18, 0x62, 0x15, 0x02, 0x03, 0x0F, 0x07, 0x0F,
	0x0B, 0x0F, 0x14, 0xA2, 0x15, 0x69, 0x23, 0x61, 0x70, 0x70, 0x2E, 0x73, 0x75, 0x69, 0x74,
	0x03, 0x58, 0x24, 0x82, 0x2F, 0x58, 0x20, 0xDA, 0x37, 0x33, 0x37, 0xCB, 0x1E, 0x25, 0xAB,
	0x21, 0xCE, 0x03, 0x04, 0x5F, 0xE0, 0xA4, 0x3D, 0xEF, 0x99, 0xC8, 0x0A, 0xFD, 0xB7, 0xEC,
	0x12, 0x10, 0x71, 0x2B, 0xA0, 0xFA, 0xC9, 0xAE, 0x9D, 0x15, 0x02, 0x03, 0x0F, 0x07, 0x0F,
	0x0B, 0x0F, 0x17, 0x82, 0x2F, 0x58, 0x20, 0xB8, 0x36, 0xCD, 0xE4, 0x01, 0x13, 0xBD, 0x77,
	0x5D, 0xE0, 0xEC, 0x07, 0xFC, 0x3E, 0xBC, 0x5F, 0x36, 0x8F, 0x8C, 0xA5, 0x05, 0xC2, 0x78,
	0x7D, 0x1A, 0xED, 0x46, 0xAB, 0x8F, 0x6B, 0x05, 0x89, 0x05, 0x82, 0x4C, 0x6B, 0x49, 0x4E,
	0x53, 0x54, 0x4C, 0x44, 0x5F, 0x4D, 0x46, 0x53, 0x54, 0x50, 0x3F, 0x6A, 0x3A, 0x4D, 0xCD,
	0xFA, 0x58, 0xC5, 0xAC, 0xCE, 0xF9, 0xF5, 0x84, 0xC4, 0x11, 0x24, 0x17, 0x58, 0x84, 0xA1,
	0x62, 0x65, 0x6E, 0xA1, 0x82, 0x4A, 0x69, 0x43, 0x41, 0x4E, 0x44, 0x5F, 0x4D, 0x46, 0x53,
	0x54, 0x41, 0x00, 0xA6, 0x01, 0x78, 0x18, 0x4E, 0x6F, 0x72, 0x64, 0x69, 0x63, 0x20, 0x53,
	0x65, 0x6D, 0x69, 0x63, 0x6F, 0x6E, 0x64, 0x75, 0x63, 0x74, 0x6F, 0x72, 0x20, 0x41, 0x53,
	0x41, 0x02, 0x68, 0x6E, 0x52, 0x46, 0x35, 0x34, 0x48, 0x32, 0x30, 0x03, 0x6E, 0x6E, 0x6F,
	0x72, 0x64, 0x69, 0x63, 0x73, 0x65, 0x6D, 0x69, 0x2E, 0x63, 0x6F, 0x6D, 0x04, 0x78, 0x1A,
	0x54, 0x68, 0x65, 0x20, 0x6E, 0x52, 0x46, 0x35, 0x34, 0x48, 0x32, 0x30, 0x20, 0x72, 0x6F,
	0x6F, 0x74, 0x20, 0x6D, 0x61, 0x6E, 0x69, 0x66, 0x65, 0x73, 0x74, 0x05, 0x74, 0x53, 0x61,
	0x6D, 0x70, 0x6C, 0x65, 0x20, 0x72, 0x6F, 0x6F, 0x74, 0x20, 0x6D, 0x61, 0x6E, 0x69, 0x66,
	0x65, 0x73, 0x74, 0x06, 0x66, 0x76, 0x31, 0x2E, 0x30, 0x2E, 0x30, 0x69, 0x23, 0x72, 0x61,
	0x64, 0x2E, 0x73, 0x75, 0x69, 0x74, 0x59, 0x02, 0xFB, 0xD8, 0x6B, 0xA4, 0x02, 0x58, 0x7A,
	0x82, 0x58, 0x24, 0x82, 0x2F, 0x58, 0x20, 0x8A, 0x63, 0x1C, 0x5B, 0x6D, 0xE8, 0x37, 0x82,
	0xB0, 0x4A, 0xDC, 0x63, 0x26, 0xC0, 0x3D, 0xA9, 0x28, 0x16, 0xE1, 0xA5, 0xB4, 0x2D, 0xB5,
	0x7D, 0xA8, 0xA0, 0x3C, 0x19, 0x81, 0x5F, 0x8E, 0xF5, 0x58, 0x51, 0xD2, 0x84, 0x4A, 0xA2,
	0x01, 0x26, 0x04, 0x45, 0x1A, 0x40, 0x03, 0x21, 0x00, 0xA0, 0xF6, 0x58, 0x40, 0x11, 0x6B,
	0x0F, 0x84, 0x71, 0x3E, 0xA6, 0xD0, 0xA5, 0x07, 0x12, 0x81, 0x9A, 0x0C, 0xC6, 0x0B, 0x96,
	0x9D, 0x4A, 0x57, 0x5B, 0x23, 0x61, 0xC2, 0x68, 0x8C, 0x23, 0x2A, 0xB9, 0x95, 0x2D, 0x38,
	0x2B, 0x24, 0x56, 0xC6, 0xF4, 0x58, 0xAC, 0xFD, 0x22, 0xF2, 0x7E, 0x8C, 0x76, 0x16, 0xF7,
	0xF8, 0xFB, 0x66, 0xB3, 0xC9, 0x28, 0xB2, 0x17, 0x3C, 0xA9, 0x25, 0x34, 0x6C, 0xC8, 0xDD,
	0xD2, 0xF1, 0x03, 0x58, 0xDB, 0xA8, 0x01, 0x01, 0x02, 0x01, 0x03, 0x58, 0x70, 0xA2, 0x02,
	0x81, 0x84, 0x44, 0x63, 0x4D, 0x45, 0x4D, 0x41, 0x03, 0x45, 0x1A, 0x0E, 0x05, 0x40, 0x00,
	0x45, 0x1A, 0x00, 0x05, 0x58, 0x00, 0x04, 0x58, 0x56, 0x86, 0x14, 0xA4, 0x01, 0x50, 0x76,
	0x17, 0xDA, 0xA5, 0x71, 0xFD, 0x5A, 0x85, 0x8F, 0x94, 0xE2, 0x8D, 0x73, 0x5C, 0xE9, 0xF4,
	0x02, 0x50, 0x81, 0x6A, 0xA0, 0xA0, 0xAF, 0x11, 0x5E, 0xF2, 0x85, 0x8A, 0xFE, 0xB6, 0x68,
	0xB2, 0xE9, 0xC9, 0x03, 0x58, 0x24, 0x82, 0x2F, 0x58, 0x20, 0x5F, 0xC3, 0x54, 0xBF, 0x8E,
	0x8C, 0x50, 0xFB, 0x4F, 0xBC, 0x2C, 0xFA, 0xEB, 0x04, 0x53, 0x41, 0xC9, 0x80, 0x6D, 0xEA,
	0xBD, 0xCB, 0x41, 0x54, 0xFB, 0x79, 0xCC, 0xA4, 0xF0, 0xC9, 0x8C, 0x12, 0x0E, 0x19, 0x01,
	0x00, 0x01, 0x0F, 0x02, 0x0F, 0x07, 0x43, 0x82, 0x03, 0x0F, 0x09, 0x43, 0x82, 0x17, 0x02,
	0x11, 0x52, 0x86, 0x14, 0xA1, 0x15, 0x69, 0x23, 0x66, 0x69, 0x6C, 0x65, 0x2E, 0x62, 0x69,
	0x6E, 0x15, 0x02, 0x03, 0x0F, 0x17, 0x82, 0x2F, 0x58, 0x20, 0xCB, 0xAC, 0xBD, 0x31, 0x77,
	0xE4, 0x07, 0x2A, 0xAB, 0x23, 0xE7, 0xED, 0x4B, 0x4B, 0x25, 0x76, 0x85, 0x87, 0xCE, 0xBB,
	0xD7, 0x53, 0xCD, 0x25, 0x68, 0x36, 0x51, 0xD0, 0x7B, 0x40, 0x3D, 0x98, 0x05, 0x82, 0x4C,
	0x6B, 0x49, 0x4E, 0x53, 0x54, 0x4C, 0x44, 0x5F, 0x4D, 0x46, 0x53, 0x54, 0x50, 0x81, 0x6A,
	0xA0, 0xA0, 0xAF, 0x11, 0x5E, 0xF2, 0x85, 0x8A, 0xFE, 0xB6, 0x68, 0xB2, 0xE9, 0xC9, 0x17,
	0x58, 0x8D, 0xA1, 0x62, 0x65, 0x6E, 0xA1, 0x84, 0x44, 0x63, 0x4D, 0x45, 0x4D, 0x41, 0x03,
	0x45, 0x1A, 0x0E, 0x05, 0x40, 0x00, 0x45, 0x1A, 0x00, 0x05, 0x58, 0x00, 0xA6, 0x01, 0x78,
	0x18, 0x4E, 0x6F, 0x72, 0x64, 0x69, 0x63, 0x20, 0x53, 0x65, 0x6D, 0x69, 0x63, 0x6F, 0x6E,
	0x64, 0x75, 0x63, 0x74, 0x6F, 0x72, 0x20, 0x41, 0x53, 0x41, 0x02, 0x6F, 0x6E, 0x52, 0x46,
	0x35, 0x34, 0x48, 0x32, 0x30, 0x5F, 0x63, 0x70, 0x75, 0x72, 0x61, 0x64, 0x03, 0x6E, 0x6E,
	0x6F, 0x72, 0x64, 0x69, 0x63, 0x73, 0x65, 0x6D, 0x69, 0x2E, 0x63, 0x6F, 0x6D, 0x04, 0x77,
	0x54, 0x68, 0x65, 0x20, 0x6E, 0x52, 0x46, 0x35, 0x34, 0x48, 0x32, 0x30, 0x20, 0x72, 0x61,
	0x64, 0x69, 0x6F, 0x20, 0x63, 0x6F, 0x72, 0x65, 0x05, 0x74, 0x53, 0x61, 0x6D, 0x70, 0x6C,
	0x65, 0x20, 0x72, 0x61, 0x64, 0x69, 0x6F, 0x20, 0x63, 0x6F, 0x72, 0x65, 0x20, 0x46, 0x57,
	0x06, 0x66, 0x76, 0x31, 0x2E, 0x30, 0x2E, 0x30, 0x69, 0x23, 0x66, 0x69, 0x6C, 0x65, 0x2E,
	0x62, 0x69, 0x6E, 0x59, 0x01, 0x00, 0xC7, 0x9C, 0xAB, 0x9D, 0xE8, 0x33, 0x7F, 0x30, 0x14,
	0xEB, 0xAC, 0x02, 0xAF, 0x26, 0x01, 0x5E, 0x80, 0x6D, 0x88, 0xA1, 0xDB, 0x11, 0xA7, 0x31,
	0xDF, 0xA6, 0xEC, 0xCB, 0x9B, 0x48, 0x0D, 0xC8, 0x34, 0x40, 0x6D, 0x30, 0x86, 0x7D, 0xE8,
	0x1B, 0xEC, 0x3C, 0xF5, 0x40, 0xD0, 0x48, 0x18, 0x82, 0x11, 0x9D, 0x7C, 0x3F, 0x6C, 0xE5,
	0x8F, 0xF1, 0xD3, 0x5D, 0xE1, 0x51, 0xF7, 0x6A, 0x0F, 0xAF, 0x0B, 0xBD, 0x4C, 0x5F, 0xA5,
	0x34, 0x1A, 0x66, 0xDB, 0x22, 0xEC, 0x63, 0xED, 0x4B, 0xAB, 0xC7, 0xC8, 0xF7, 0x59, 0xD8,
	0xD6, 0x9E, 0xEC, 0x71, 0x1B, 0x24, 0x20, 0xB9, 0xAE, 0xE1, 0x3B, 0xFC, 0xAE, 0xB8, 0x77,
	0xAC, 0xA4, 0x57, 0x34, 0x97, 0x84, 0x4F, 0x58, 0xD5, 0x68, 0x08, 0x6F, 0xE3, 0x9C, 0x7E,
	0x1B, 0xD7, 0x38, 0x22, 0x98, 0x48, 0xF8, 0x7A, 0x67, 0xB2, 0xD9, 0xAC, 0xC5, 0x34, 0xC1,
	0x27, 0x82, 0x8E, 0x42, 0x79, 0x84, 0x21, 0x37, 0x4C, 0x41, 0x4A, 0x0F, 0xE2, 0x7F, 0xA0,
	0x6A, 0x19, 0x13, 0x3D, 0x52, 0x22, 0x7F, 0xD6, 0x2F, 0x71, 0x12, 0x76, 0xAB, 0x25, 0x9C,
	0xFC, 0x67, 0x08, 0x03, 0x7C, 0xDB, 0x18, 0xE6, 0x45, 0xF8, 0x99, 0xC2, 0x9E, 0x2C, 0xE3,
	0x9B, 0x25, 0xA9, 0x7B, 0x09, 0xFF, 0x00, 0x57, 0x26, 0x08, 0x0A, 0x11, 0x42, 0xCF, 0x82,
	0xA2, 0x6B, 0x2A, 0x99, 0xF9, 0x71, 0x9D, 0x14, 0x19, 0x5C, 0x5C, 0x78, 0x31, 0x60, 0x42,
	0x4A, 0x18, 0x1F, 0xEC, 0x78, 0x6A, 0x9A, 0x7C, 0x4F, 0xCF, 0xE8, 0x5A, 0x29, 0x65, 0xCD,
	0x01, 0x3B, 0x6D, 0x53, 0xBB, 0xC6, 0xDB, 0xDA, 0xD5, 0x8F, 0xF7, 0xF4, 0xD9, 0xB9, 0x0A,
	0x03, 0x4B, 0xFF, 0x33, 0xAB, 0x3B, 0xC5, 0xAF, 0xD0, 0xB8, 0x2C, 0x0F, 0x6A, 0xA9, 0x11,
	0xB0, 0xE8, 0x57, 0x8C, 0x92, 0x53, 0x81, 0x69, 0x23, 0x61, 0x70, 0x70, 0x2E, 0x73, 0x75,
	0x69, 0x74, 0x59, 0x03, 0x09, 0xD8, 0x6B, 0xA4, 0x02, 0x58, 0x7A, 0x82, 0x58, 0x24, 0x82,
	0x2F, 0x58, 0x20, 0x4E, 0xDE, 0x20, 0x62, 0xD7, 0x21, 0x32, 0xB2, 0xF4, 0x4C, 0x2C, 0x8B,
	0x10, 0x41, 0xB1, 0x76, 0x3C, 0x6E, 0x42, 0x2A, 0x82, 0xE9, 0x95, 0x91, 0x2B, 0x3B, 0x3A,
	0x41, 0xC7, 0x96, 0xA3, 0x9B, 0x58, 0x51, 0xD2, 0x84, 0x4A, 0xA2, 0x01, 0x26, 0x04, 0x45,
	0x1A, 0x40, 0x02, 0x21, 0x00, 0xA0, 0xF6, 0x58, 0x40, 0x39, 0x9A, 0x16, 0x37, 0xEC, 0x61,
	0xA4, 0x17, 0x40, 0x22, 0xE7, 0x0B, 0xA4, 0x9F, 0x37, 0x93, 0xC9, 0x32, 0xD9, 0x6A, 0x16,
	0x42, 0x10, 0x2E, 0xB9, 0x59, 0x62, 0x1C, 0x04, 0x30, 0x5D, 0xB8, 0x8A, 0x86, 0x95, 0xEB,
	0x5C, 0xFC, 0x99, 0x9C, 0xE3, 0x23, 0x00, 0xB3, 0xDB, 0xE7, 0xC0, 0x60, 0x56, 0x72, 0x6D,
	0x7C, 0xD0, 0x94, 0x69, 0xB1, 0x72, 0x64, 0xDD, 0x79, 0x44, 0x05, 0x18, 0xBC, 0x03, 0x58,
	0xDB, 0xA8, 0x01, 0x01, 0x02, 0x01, 0x03, 0x58, 0x70, 0xA2, 0x02, 0x81, 0x84, 0x44, 0x63,
	0x4D, 0x45, 0x4D, 0x41, 0x02, 0x45, 0x1A, 0x0E, 0x0A, 0xA0, 0x00, 0x45, 0x1A, 0x00, 0x07,
	0xF8, 0x00, 0x04, 0x58, 0x56, 0x86, 0x14, 0xA4, 0x01, 0x50, 0x76, 0x17, 0xDA, 0xA5, 0x71,
	0xFD, 0x5A, 0x85, 0x8F, 0x94, 0xE2, 0x8D, 0x73, 0x5C, 0xE9, 0xF4, 0x02, 0x50, 0x08, 0xC1,
	0xB5, 0x99, 0x55, 0xE8, 0x5F, 0xBC, 0x9E, 0x76, 0x7B, 0xC2, 0x9C, 0xE1, 0xB0, 0x4D, 0x03,
	0x58, 0x24, 0x82, 0x2F, 0x58, 0x20, 0x5F, 0xC3, 0x54, 0xBF, 0x8E, 0x8C, 0x50, 0xFB, 0x4F,
	0xBC, 0x2C, 0xFA, 0xEB, 0x04, 0x53, 0x41, 0xC9, 0x80, 0x6D, 0xEA, 0xBD, 0xCB, 0x41, 0x54,
	0xFB, 0x79, 0xCC, 0xA4, 0xF0, 0xC9, 0x8C, 0x12, 0x0E, 0x19, 0x01, 0x00, 0x01, 0x0F, 0x02,
	0x0F, 0x07, 0x43, 0x82, 0x03, 0x0F, 0x09, 0x43, 0x82, 0x17, 0x02, 0x11, 0x52, 0x86, 0x14,
	0xA1, 0x15, 0x69, 0x23, 0x66, 0x69, 0x6C, 0x65, 0x2E, 0x62, 0x69, 0x6E, 0x15, 0x02, 0x03,
	0x0F, 0x17, 0x82, 0x2F, 0x58, 0x20, 0x47, 0x37, 0x59, 0x1A, 0x1E, 0x62, 0xE1, 0x47, 0xD3,
	0x22, 0x73, 0xA9, 0x14, 0x4C, 0x55, 0xD9, 0x90, 0xA8, 0x51, 0x41, 0x8C, 0x82, 0x68, 0x30,
	0x4C, 0xE1, 0x6F, 0x23, 0x6F, 0x26, 0x5D, 0x13, 0x05, 0x82, 0x4C, 0x6B, 0x49, 0x4E, 0x53,
	0x54, 0x4C, 0x44, 0x5F, 0x4D, 0x46, 0x53, 0x54, 0x50, 0x08, 0xC1, 0xB5, 0x99, 0x55, 0xE8,
	0x5F, 0xBC, 0x9E, 0x76, 0x7B, 0xC2, 0x9C, 0xE1, 0xB0, 0x4D, 0x17, 0x58, 0x9B, 0xA1, 0x62,
	0x65, 0x6E, 0xA1, 0x84, 0x44, 0x63, 0x4D, 0x45, 0x4D, 0x41, 0x02, 0x45, 0x1A, 0x0E, 0x0A,
	0xA0, 0x00, 0x45, 0x1A, 0x00, 0x07, 0xF8, 0x00, 0xA6, 0x01, 0x78, 0x18, 0x4E, 0x6F, 0x72,
	0x64, 0x69, 0x63, 0x20, 0x53, 0x65, 0x6D, 0x69, 0x63, 0x6F, 0x6E, 0x64, 0x75, 0x63, 0x74,
	0x6F, 0x72, 0x20, 0x41, 0x53, 0x41, 0x02, 0x6F, 0x6E, 0x52, 0x46, 0x35, 0x34, 0x48, 0x32,
	0x30, 0x5F, 0x63, 0x70, 0x75, 0x61, 0x70, 0x70, 0x03, 0x6E, 0x6E, 0x6F, 0x72, 0x64, 0x69,
	0x63, 0x73, 0x65, 0x6D, 0x69, 0x2E, 0x63, 0x6F, 0x6D, 0x04, 0x78, 0x1D, 0x54, 0x68, 0x65,
	0x20, 0x6E, 0x52, 0x46, 0x35, 0x34, 0x48, 0x32, 0x30, 0x20, 0x61, 0x70, 0x70, 0x6C, 0x69,
	0x63, 0x61, 0x74, 0x69, 0x6F, 0x6E, 0x20, 0x63, 0x6F, 0x72, 0x65, 0x05, 0x78, 0x1A, 0x53,
	0x61, 0x6D, 0x70, 0x6C, 0x65, 0x20, 0x61, 0x70, 0x70, 0x6C, 0x69, 0x63, 0x61, 0x74, 0x69,
	0x6F, 0x6E, 0x20, 0x63, 0x6F, 0x72, 0x65, 0x20, 0x46, 0x57, 0x06, 0x66, 0x76, 0x31, 0x2E,
	0x30, 0x2E, 0x30, 0x69, 0x23, 0x66, 0x69, 0x6C, 0x65, 0x2E, 0x62, 0x69, 0x6E, 0x59, 0x01,
	0x00, 0xC7, 0x9C, 0xAB, 0x9D, 0xE8, 0x33, 0x7F, 0x30, 0x14, 0xEB, 0xAC, 0x02, 0xAF, 0x26,
	0x01, 0x5E, 0x80, 0x6D, 0x88, 0xA1, 0xDB, 0x11, 0xA7, 0x31, 0xDF, 0xA6, 0xEC, 0xCB, 0x9B,
	0x48, 0x0D, 0xC8, 0x34, 0x40, 0x6D, 0x30, 0x86, 0x7D, 0xE8, 0x1B, 0xEC, 0x3C, 0xF5, 0x40,
	0xD0, 0x48, 0x18, 0x82, 0x11, 0x9D, 0x7C, 0x3F, 0x6C, 0xE5, 0x8F, 0xF1, 0xD3, 0x5D, 0xE1,
	0x51, 0xF7, 0x6A, 0x0F, 0xAF, 0x0B, 0xBD, 0x4C, 0x5F, 0xA5, 0x34, 0x1A, 0x66, 0xDB, 0x22,
	0xEC, 0x63, 0xED, 0x4B, 0xAB, 0xC7, 0xC8, 0xF7, 0x59, 0xD8, 0xD6, 0x9E, 0xEC, 0x71, 0x1B,
	0x24, 0x20, 0xB9, 0xAE, 0xE1, 0x3B, 0xFC, 0xAE, 0xB8, 0x77, 0xAC, 0xA4, 0x57, 0x34, 0x97,
	0x84, 0x4F, 0x58, 0xD5, 0x68, 0x08, 0x6F, 0xE3, 0x9C, 0x7E, 0x1B, 0xD7, 0x38, 0x22, 0x98,
	0x48, 0xF8, 0x7A, 0x67, 0xB2, 0xD9, 0xAC, 0xC5, 0x34, 0xC1, 0x27, 0x82, 0x8E, 0x42, 0x79,
	0x84, 0x21, 0x37, 0x4C, 0x41, 0x4A, 0x0F, 0xE2, 0x7F, 0xA0, 0x6A, 0x19, 0x13, 0x3D, 0x52,
	0x22, 0x7F, 0xD6, 0x2F, 0x71, 0x12, 0x76, 0xAB, 0x25, 0x9C, 0xFC, 0x67, 0x08, 0x03, 0x7C,
	0xDB, 0x18, 0xE6, 0x45, 0xF8, 0x99, 0xC2, 0x9E, 0x2C, 0xE3, 0x9B, 0x25, 0xA9, 0x7B, 0x09,
	0xFF, 0x00, 0x57, 0x26, 0x08, 0x0A, 0x11, 0x42, 0xCF, 0x82, 0xA2, 0x6B, 0x2A, 0x99, 0xF9,
	0x71, 0x9D, 0x14, 0x19, 0x5C, 0x5C, 0x78, 0x31, 0x60, 0x42, 0x4A, 0x18, 0x1F, 0xEC, 0x78,
	0x6A, 0x9A, 0x7C, 0x4F, 0xCF, 0xE8, 0x5A, 0x29, 0x65, 0xCD, 0x01, 0x3B, 0x6D, 0x53, 0xBB,
	0xC6, 0xDB, 0xDA, 0xD5, 0x8F, 0xF7, 0xF4, 0xD9, 0xB9, 0x0A, 0x03, 0x4B, 0xFF, 0x33, 0xAB,
	0x3B, 0xC5, 0xAF, 0xD0, 0xB8, 0x2C, 0x0F, 0x6A, 0xA9, 0x11, 0xB0, 0xE8, 0x57, 0x8C, 0x92,
	0x53, 0x81};

const size_t manifest_root_len = sizeof(manifest_root_buf);
```

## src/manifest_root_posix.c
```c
/*
 * Copyright (c) 2023 Nordic Semiconductor ASA
 *
 * SPDX-License-Identifier: LicenseRef-Nordic-5-Clause
 */

#include <stdint.h>
#include <stddef.h>

/** @brief SUIT envelope generated using the manifest/manifest_root_posix.yaml input file.
 *
 * @details This envelope contains 256-byte random numbers attached as an integrated
 *          payload and fetched directly into the memory-mapped region during install step.
 *          The envelope has been signed using the manifest/key_private.pem key.
 *
 * @note Please use the manifest_common/regenerate.sh script for regenerating payloads.
 */
uint8_t manifest_root_posix_buf[] = {
	0xD8, 0x6B, 0xA4, 0x02, 0x58, 0x7A, 0x82, 0x58, 0x24, 0x82, 0x2F, 0x58, 0x20, 0xA0, 0xC8,
	0x2A, 0x76, 0xFD, 0xD9, 0xF6, 0x87, 0x6E, 0xA5, 0xF4, 0x46, 0xED, 0x1D, 0x64, 0xCF, 0xBF,
	0xEE, 0x64, 0x3E, 0x2F, 0xCA, 0x4E, 0xBA, 0x98, 0x07, 0x6A, 0xB4, 0xC8, 0xCF, 0x3F, 0xA8,
	0x58, 0x51, 0xD2, 0x84, 0x4A, 0xA2, 0x01, 0x26, 0x04, 0x45, 0x1A, 0x40, 0x00, 0x00, 0x00,
	0xA0, 0xF6, 0x58, 0x40, 0x88, 0xB0, 0xFD, 0xD3, 0x7D, 0x78, 0x2F, 0xD8, 0x6D, 0x43, 0xCE,
	0x60, 0xD4, 0xBA, 0xB6, 0x3D, 0x07, 0xE3, 0x04, 0xCA, 0x7E, 0x65, 0xA0, 0x2A, 0xA8, 0x65,
	0x93, 0xD6, 0x00, 0x5D, 0xAF, 0x77, 0x33, 0x75, 0xCC, 0x62, 0x13, 0x98, 0xFB, 0xFA, 0xCD,
	0x65, 0x5A, 0x00, 0xE6, 0x63, 0x50, 0x91, 0xB5, 0x70, 0xF6, 0x9E, 0xCE, 0xD3, 0xC2, 0x46,
	0x2C, 0x2A, 0xD8, 0xD3, 0x77, 0x70, 0xD0, 0x1A, 0x03, 0x59, 0x01, 0x09, 0xA8, 0x01, 0x01,
	0x02, 0x01, 0x03, 0x58, 0x68, 0xA3, 0x02, 0x82, 0x82, 0x4A, 0x69, 0x43, 0x41, 0x4E, 0x44,
	0x5F, 0x4D, 0x46, 0x53, 0x54, 0x41, 0x00, 0x82, 0x4C, 0x6B, 0x49, 0x4E, 0x53, 0x54, 0x4C,
	0x44, 0x5F, 0x4D, 0x46, 0x53, 0x54, 0x50, 0x5B, 0x46, 0x9F, 0xD1, 0x90, 0xEE, 0x53, 0x9C,
	0xA3, 0x18, 0x68, 0x1B, 0x03, 0x69, 0x5E, 0x36, 0x04, 0x58, 0x2F, 0x8A, 0x0C, 0x01, 0x14,
	0xA2, 0x01, 0x50, 0x76, 0x17, 0xDA, 0xA5, 0x71, 0xFD, 0x5A, 0x85, 0x8F, 0x94, 0xE2, 0x8D,
	0x73, 0x5C, 0xE9, 0xF4, 0x02, 0x50, 0x5B, 0x46, 0x9F, 0xD1, 0x90, 0xEE, 0x53, 0x9C, 0xA3,
	0x18, 0x68, 0x1B, 0x03, 0x69, 0x5E, 0x36, 0x0C, 0x01, 0x01, 0x0F, 0x02, 0x0F, 0x01, 0xA2,
	0x00, 0xA0, 0x01, 0xA0, 0x07, 0x47, 0x86, 0x0C, 0x01, 0x07, 0x0F, 0x0B, 0x0F, 0x09, 0x47,
	0x86, 0x0C, 0x01, 0x07, 0x0F, 0x0B, 0x0F, 0x11, 0x58, 0x3F, 0x8C, 0x0C, 0x00, 0x14, 0xA2,
	0x15, 0x69, 0x23, 0x61, 0x70, 0x70, 0x2E, 0x73, 0x75, 0x69, 0x74, 0x03, 0x58, 0x24, 0x82,
	0x2F, 0x58, 0x20, 0x65, 0x3D, 0x93, 0x0A, 0x71, 0x9A, 0x25, 0xF9, 0xBB, 0x5A, 0x92, 0x39,
	0x62, 0x78, 0x10, 0x5D, 0xF4, 0x89, 0x15, 0x05, 0xCD, 0x09, 0x2B, 0xE1, 0x02, 0x3F, 0x3D,
	0xDE, 0x17, 0xC5, 0xA5, 0xB3, 0x15, 0x02, 0x03, 0x0F, 0x07, 0x0F, 0x0B, 0x0F, 0x17, 0x82,
	0x2F, 0x58, 0x20, 0x45, 0x5E, 0x9B, 0x02, 0x97, 0xB3, 0xBB, 0xA3, 0xEC, 0x89, 0xBA, 0xD9,
	0x6F, 0x09, 0x7C, 0x12, 0xA7, 0x4D, 0x3E, 0xDC, 0x1F, 0xB2, 0x40, 0x3F, 0x4A, 0x36, 0xA5,
	0x5C, 0x82, 0x24, 0x9D, 0x84, 0x05, 0x82, 0x4C, 0x6B, 0x49, 0x4E, 0x53, 0x54, 0x4C, 0x44,
	0x5F, 0x4D, 0x46, 0x53, 0x54, 0x50, 0x97, 0x05, 0x48, 0x23, 0x4C, 0x3D, 0x59, 0xA1, 0x89,
	0x86, 0xA5, 0x46, 0x60, 0xA1, 0x4B, 0x0A, 0x17, 0x58, 0x7D, 0xA1, 0x62, 0x65, 0x6E, 0xA1,
	0x82, 0x4A, 0x69, 0x43, 0x41, 0x4E, 0x44, 0x5F, 0x4D, 0x46, 0x53, 0x54, 0x41, 0x00, 0xA6,
	0x01, 0x78, 0x18, 0x4E, 0x6F, 0x72, 0x64, 0x69, 0x63, 0x20, 0x53, 0x65, 0x6D, 0x69, 0x63,
	0x6F, 0x6E, 0x64, 0x75, 0x63, 0x74, 0x6F, 0x72, 0x20, 0x41, 0x53, 0x41, 0x02, 0x65, 0x70,
	0x6F, 0x73, 0x69, 0x78, 0x03, 0x6E, 0x6E, 0x6F, 0x72, 0x64, 0x69, 0x63, 0x73, 0x65, 0x6D,
	0x69, 0x2E, 0x63, 0x6F, 0x6D, 0x04, 0x77, 0x54, 0x68, 0x65, 0x20, 0x50, 0x4F, 0x53, 0x49,
	0x58, 0x20, 0x72, 0x6F, 0x6F, 0x74, 0x20, 0x6D, 0x61, 0x6E, 0x69, 0x66, 0x65, 0x73, 0x74,
	0x05, 0x74, 0x53, 0x61, 0x6D, 0x70, 0x6C, 0x65, 0x20, 0x72, 0x6F, 0x6F, 0x74, 0x20, 0x6D,
	0x61, 0x6E, 0x69, 0x66, 0x65, 0x73, 0x74, 0x06, 0x66, 0x76, 0x31, 0x2E, 0x30, 0x2E, 0x30,
	0x69, 0x23, 0x61, 0x70, 0x70, 0x2E, 0x73, 0x75, 0x69, 0x74, 0x59, 0x02, 0xF4, 0xD8, 0x6B,
	0xA4, 0x02, 0x58, 0x7A, 0x82, 0x58, 0x24, 0x82, 0x2F, 0x58, 0x20, 0xDF, 0x79, 0x9F, 0x6C,
	0xEB, 0x40, 0x2C, 0x68, 0x1F, 0x1A, 0x36, 0x49, 0x79, 0x88, 0x83, 0xF3, 0x8A, 0x6D, 0xA9,
	0x81, 0x08, 0xA1, 0xA8, 0xE3, 0x72, 0xA0, 0xF7, 0x01, 0x27, 0x4C, 0xE9, 0x75, 0x58, 0x51,
	0xD2, 0x84, 0x4A, 0xA2, 0x01, 0x26, 0x04, 0x45, 0x1A, 0x40, 0x00, 0x00, 0x00, 0xA0, 0xF6,
	0x58, 0x40, 0xB6, 0xA9, 0xAB, 0x2B, 0xCA, 0x46, 0xB7, 0xCE, 0x18, 0x3D, 0xF1, 0x42, 0xA1,
	0xFE, 0xFE, 0x8F, 0x92, 0x4E, 0xC4, 0x3F, 0x96, 0xA9, 0x63, 0xFC, 0xD2, 0x1C, 0xDC, 0x05,
	0x07, 0x09, 0x38, 0x3C, 0x8B, 0x4D, 0x73, 0xEC, 0xF8, 0x90, 0x59, 0xCB, 0x4A, 0x58, 0x61,
	0xA6, 0x31, 0x55, 0xE4, 0xD3, 0xCF, 0xF2, 0xAA, 0x20, 0xDD, 0x4D, 0x51, 0x1B, 0xC6, 0xF4,
	0x16, 0x22, 0x65, 0x0E, 0x16, 0x48, 0x03, 0x58, 0xD9, 0xA8, 0x01, 0x01, 0x02, 0x01, 0x03,
	0x58, 0x6E, 0xA2, 0x02, 0x81, 0x84, 0x44, 0x63, 0x4D, 0x45, 0x4D, 0x41, 0x00, 0x45, 0x1A,
	0x00, 0x08, 0x00, 0x00, 0x43, 0x19, 0x10, 0x00, 0x04, 0x58, 0x56, 0x86, 0x14, 0xA4, 0x01,
	0x50, 0x76, 0x17, 0xDA, 0xA5, 0x71, 0xFD, 0x5A, 0x85, 0x8F, 0x94, 0xE2, 0x8D, 0x73, 0x5C,
	0xE9, 0xF4, 0x02, 0x50, 0x5B, 0x46, 0x9F, 0xD1, 0x90, 0xEE, 0x53, 0x9C, 0xA3, 0x18, 0x68,
	0x1B, 0x03, 0x69, 0x5E, 0x36, 0x03, 0x58, 0x24, 0x82, 0x2F, 0x58, 0x20, 0x5F, 0xC3, 0x54,
	0xBF, 0x8E, 0x8C, 0x50, 0xFB, 0x4F, 0xBC, 0x2C, 0xFA, 0xEB, 0x04, 0x53, 0x41, 0xC9, 0x80,
	0x6D, 0xEA, 0xBD, 0xCB, 0x41, 0x54, 0xFB, 0x79, 0xCC, 0xA4, 0xF0, 0xC9, 0x8C, 0x12, 0x0E,
	0x19, 0x01, 0x00, 0x01, 0x0F, 0x02, 0x0F, 0x07, 0x43, 0x82, 0x03, 0x0F, 0x09, 0x43, 0x82,
	0x17, 0x02, 0x11, 0x52, 0x86, 0x14, 0xA1, 0x15, 0x69, 0x23, 0x66, 0x69, 0x6C, 0x65, 0x2E,
	0x62, 0x69, 0x6E, 0x15, 0x02, 0x03, 0x0F, 0x17, 0x82, 0x2F, 0x58, 0x20, 0x62, 0x2B, 0x04,
	0x96, 0xCA, 0x8F, 0x04, 0xCF, 0x83, 0x2F, 0x65, 0x90, 0xD2, 0x2A, 0x16, 0x52, 0x51, 0xB5,
	0xA9, 0xFB, 0x08, 0xF6, 0xE4, 0x35, 0x3D, 0x01, 0xE3, 0x3E, 0xA7, 0xCA, 0xC5, 0x86, 0x05,
	0x82, 0x4C, 0x6B, 0x49, 0x4E, 0x53, 0x54, 0x4C, 0x44, 0x5F, 0x4D, 0x46, 0x53, 0x54, 0x50,
	0x5B, 0x46, 0x9F, 0xD1, 0x90, 0xEE, 0x53, 0x9C, 0xA3, 0x18, 0x68, 0x1B, 0x03, 0x69, 0x5E,
	0x36, 0x17, 0x58, 0x88, 0xA1, 0x62, 0x65, 0x6E, 0xA1, 0x84, 0x44, 0x63, 0x4D, 0x45, 0x4D,
	0x41, 0x00, 0x45, 0x1A, 0x00, 0x08, 0x00, 0x00, 0x43, 0x19, 0x10, 0x00, 0xA6, 0x01, 0x78,
	0x18, 0x4E, 0x6F, 0x72, 0x64, 0x69, 0x63, 0x20, 0x53, 0x65, 0x6D, 0x69, 0x63, 0x6F, 0x6E,
	0x64, 0x75, 0x63, 0x74, 0x6F, 0x72, 0x20, 0x41, 0x53, 0x41, 0x02, 0x65, 0x70, 0x6F, 0x73,
	0x69, 0x78, 0x03, 0x6E, 0x6E, 0x6F, 0x72, 0x64, 0x69, 0x63, 0x73, 0x65, 0x6D, 0x69, 0x2E,
	0x63, 0x6F, 0x6D, 0x04, 0x75, 0x54, 0x68, 0x65, 0x20, 0x50, 0x4F, 0x53, 0x49, 0x58, 0x20,
	0x61, 0x70, 0x70, 0x6C, 0x69, 0x63, 0x61, 0x74, 0x69, 0x6F, 0x6E, 0x05, 0x78, 0x1C, 0x53,
	0x61, 0x6D, 0x70, 0x6C, 0x65, 0x20, 0x61, 0x70, 0x70, 0x6C, 0x69, 0x63, 0x61, 0x74, 0x69,
	0x6F, 0x6E, 0x20, 0x66, 0x6F, 0x72, 0x20, 0x50, 0x4F, 0x53, 0x49, 0x58, 0x06, 0x66, 0x76,
	0x31, 0x2E, 0x30, 0x2E, 0x30, 0x69, 0x23, 0x66, 0x69, 0x6C, 0x65, 0x2E, 0x62, 0x69, 0x6E,
	0x59, 0x01, 0x00, 0xC7, 0x9C, 0xAB, 0x9D, 0xE8, 0x33, 0x7F, 0x30, 0x14, 0xEB, 0xAC, 0x02,
	0xAF, 0x26, 0x01, 0x5E, 0x80, 0x6D, 0x88, 0xA1, 0xDB, 0x11, 0xA7, 0x31, 0xDF, 0xA6, 0xEC,
	0xCB, 0x9B, 0x48, 0x0D, 0xC8, 0x34, 0x40, 0x6D, 0x30, 0x86, 0x7D, 0xE8, 0x1B, 0xEC, 0x3C,
	0xF5, 0x40, 0xD0, 0x48, 0x18, 0x82, 0x11, 0x9D, 0x7C, 0x3F, 0x6C, 0xE5, 0x8F, 0xF1, 0xD3,
	0x5D, 0xE1, 0x51, 0xF7, 0x6A, 0x0F, 0xAF, 0x0B, 0xBD, 0x4C, 0x5F, 0xA5, 0x34, 0x1A, 0x66,
	0xDB, 0x22, 0xEC, 0x63, 0xED, 0x4B, 0xAB, 0xC7, 0xC8, 0xF7, 0x59, 0xD8, 0xD6, 0x9E, 0xEC,
	0x71, 0x1B, 0x24, 0x20, 0xB9, 0xAE, 0xE1, 0x3B, 0xFC, 0xAE, 0xB8, 0x77, 0xAC, 0xA4, 0x57,
	0x34, 0x97, 0x84, 0x4F, 0x58, 0xD5, 0x68, 0x08, 0x6F, 0xE3, 0x9C, 0x7E, 0x1B, 0xD7, 0x38,
	0x22, 0x98, 0x48, 0xF8, 0x7A, 0x67, 0xB2, 0xD9, 0xAC, 0xC5, 0x34, 0xC1, 0x27, 0x82, 0x8E,
	0x42, 0x79, 0x84, 0x21, 0x37, 0x4C, 0x41, 0x4A, 0x0F, 0xE2, 0x7F, 0xA0, 0x6A, 0x19, 0x13,
	0x3D, 0x52, 0x22, 0x7F, 0xD6, 0x2F, 0x71, 0x12, 0x76, 0xAB, 0x25, 0x9C, 0xFC, 0x67, 0x08,
	0x03, 0x7C, 0xDB, 0x18, 0xE6, 0x45, 0xF8, 0x99, 0xC2, 0x9E, 0x2C, 0xE3, 0x9B, 0x25, 0xA9,
	0x7B, 0x09, 0xFF, 0x00, 0x57, 0x26, 0x08, 0x0A, 0x11, 0x42, 0xCF, 0x82, 0xA2, 0x6B, 0x2A,
	0x99, 0xF9, 0x71, 0x9D, 0x14, 0x19, 0x5C, 0x5C, 0x78, 0x31, 0x60, 0x42, 0x4A, 0x18, 0x1F,
	0xEC, 0x78, 0x6A, 0x9A, 0x7C, 0x4F, 0xCF, 0xE8, 0x5A, 0x29, 0x65, 0xCD, 0x01, 0x3B, 0x6D,
	0x53, 0xBB, 0xC6, 0xDB, 0xDA, 0xD5, 0x8F, 0xF7, 0xF4, 0xD9, 0xB9, 0x0A, 0x03, 0x4B, 0xFF,
	0x33, 0xAB, 0x3B, 0xC5, 0xAF, 0xD0, 0xB8, 0x2C, 0x0F, 0x6A, 0xA9, 0x11, 0xB0, 0xE8, 0x57,
	0x8C, 0x92, 0x53, 0x81};

const size_t manifest_root_posix_len = sizeof(manifest_root_posix_buf);
```
